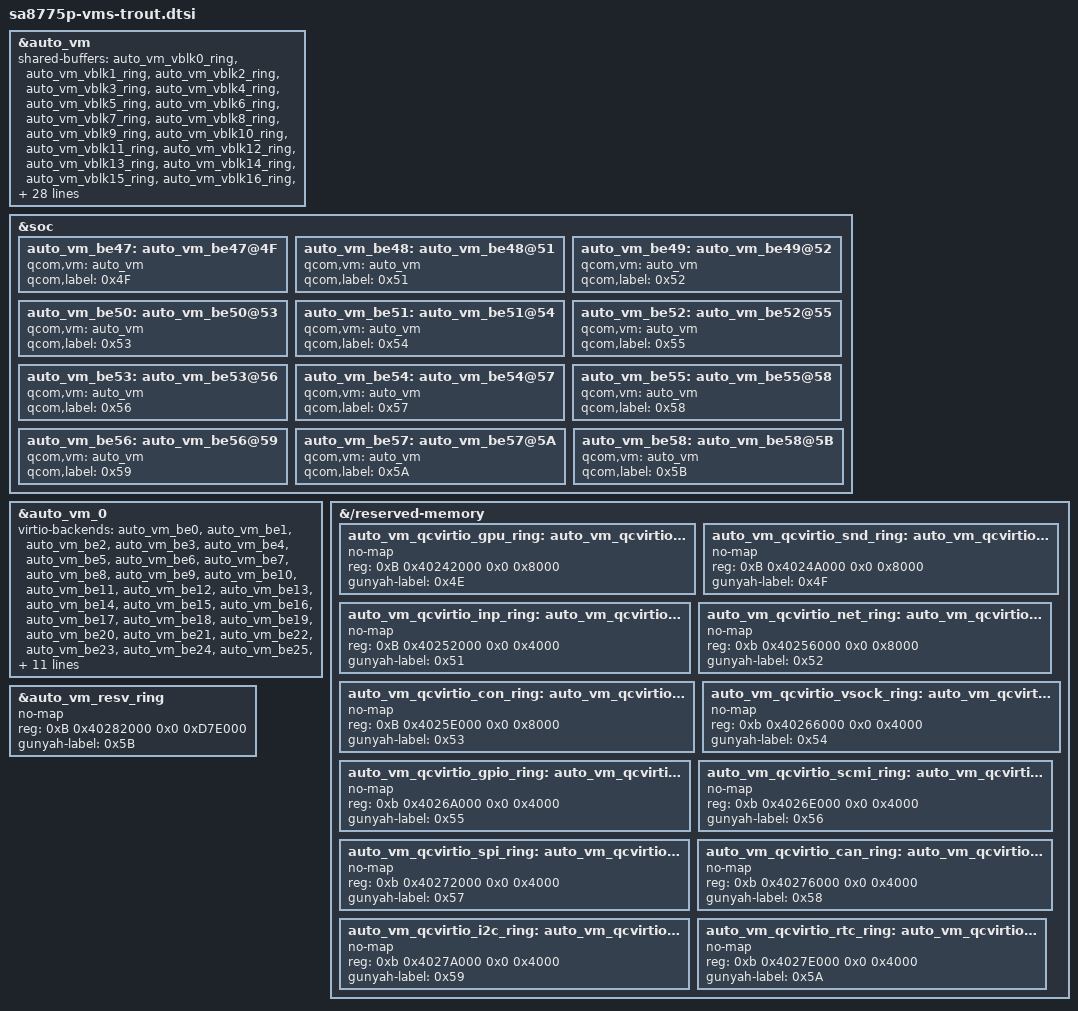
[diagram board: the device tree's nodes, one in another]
// SPDX-License-Identifier: BSD-3-Clause
/*
 * Copyright (c) Qualcomm Technologies, Inc. and/or its subsidiaries.
 */

&auto_vm {
	shared-buffers = <&auto_vm_vblk0_ring
				&auto_vm_vblk1_ring
				&auto_vm_vblk2_ring
				&auto_vm_vblk3_ring
				&auto_vm_vblk4_ring
				&auto_vm_vblk5_ring
				&auto_vm_vblk6_ring
				&auto_vm_vblk7_ring
				&auto_vm_vblk8_ring
				&auto_vm_vblk9_ring
				&auto_vm_vblk10_ring
				&auto_vm_vblk11_ring
				&auto_vm_vblk12_ring
				&auto_vm_vblk13_ring
				&auto_vm_vblk14_ring
				&auto_vm_vblk15_ring
				&auto_vm_vblk16_ring
				&auto_vm_vblk17_ring
				&auto_vm_vblk18_ring
				&auto_vm_vblk19_ring
				&auto_vm_vblk20_ring
				&auto_vm_vblk21_ring
				&auto_vm_vblk22_ring
				&auto_vm_vblk23_ring
				&auto_vm_vblk24_ring
				&auto_vm_vnet0_ring
				&auto_vm_vnet1_ring
				&auto_vm_vhab0_ring
				&auto_vm_vhab1_ring
				&auto_vm_vhab2_ring
				&auto_vm_vhab3_ring
				&auto_vm_vhab4_ring
				&auto_vm_vhab5_ring
				&auto_vm_vhab6_ring
				&auto_vm_vhab7_ring
				&auto_vm_vhab8_ring
				&auto_vm_input0_ring
				&auto_vm_input1_ring
				&auto_vm_vconsole_ring
				&auto_vm_vscmi_ring
				&auto_vm_vsock_ring
				&auto_vm_glink_ring
				&auto_vm_frpc_ring
				&auto_vm_i2c0_ring
				&auto_vm_ssr_ring
				&auto_vm_eavb_ring
				&auto_vm_qcvirtio_gpu_ring
				&auto_vm_qcvirtio_snd_ring
				&auto_vm_qcvirtio_inp_ring
				&auto_vm_qcvirtio_net_ring
				&auto_vm_qcvirtio_con_ring
				&auto_vm_qcvirtio_vsock_ring
				&auto_vm_qcvirtio_gpio_ring
				&auto_vm_qcvirtio_scmi_ring
				&auto_vm_qcvirtio_spi_ring
				&auto_vm_qcvirtio_can_ring
				&auto_vm_qcvirtio_i2c_ring
				&auto_vm_qcvirtio_rtc_ring
				&auto_vm_resv_ring
				&auto_vm_swiotlb
				>;
};

&soc {
	auto_vm_be47: auto_vm_be47@4F {
		qcom,vm = <&auto_vm>;
		qcom,label = <0x4F>;
	};

	auto_vm_be48: auto_vm_be48@51 {
		qcom,vm = <&auto_vm>;
		qcom,label = <0x51>;
	};

	auto_vm_be49: auto_vm_be49@52 {
		qcom,vm = <&auto_vm>;
		qcom,label = <0x52>;
	};

	auto_vm_be50: auto_vm_be50@53 {
		qcom,vm = <&auto_vm>;
		qcom,label = <0x53>;
	};

	auto_vm_be51: auto_vm_be51@54 {
		qcom,vm = <&auto_vm>;
		qcom,label = <0x54>;
	};

	auto_vm_be52: auto_vm_be52@55 {
		qcom,vm = <&auto_vm>;
		qcom,label = <0x55>;
	};

	auto_vm_be53: auto_vm_be53@56 {
		qcom,vm = <&auto_vm>;
		qcom,label = <0x56>;
	};

	auto_vm_be54: auto_vm_be54@57 {
		qcom,vm = <&auto_vm>;
		qcom,label = <0x57>;
	};

	auto_vm_be55: auto_vm_be55@58 {
		qcom,vm = <&auto_vm>;
		qcom,label = <0x58>;
	};

	auto_vm_be56: auto_vm_be56@59 {
		qcom,vm = <&auto_vm>;
		qcom,label = <0x59>;
	};

	auto_vm_be57: auto_vm_be57@5A {
		qcom,vm = <&auto_vm>;
		qcom,label = <0x5A>;
	};

	auto_vm_be58: auto_vm_be58@5B {
		qcom,vm = <&auto_vm>;
		qcom,label = <0x5B>;
	};
};

&auto_vm_0 {
	virtio-backends = <&auto_vm_be0
				&auto_vm_be1
				&auto_vm_be2
				&auto_vm_be3
				&auto_vm_be4
				&auto_vm_be5
				&auto_vm_be6
				&auto_vm_be7
				&auto_vm_be8
				&auto_vm_be9
				&auto_vm_be10
				&auto_vm_be11
				&auto_vm_be12
				&auto_vm_be13
				&auto_vm_be14
				&auto_vm_be15
				&auto_vm_be16
				&auto_vm_be17
				&auto_vm_be18
				&auto_vm_be19
				&auto_vm_be20
				&auto_vm_be21
				&auto_vm_be22
				&auto_vm_be23
				&auto_vm_be24
				&auto_vm_be25
				&auto_vm_be26
				&auto_vm_be27
				&auto_vm_be28
				&auto_vm_be29
				&auto_vm_be30
				&auto_vm_be31
				&auto_vm_be32
				&auto_vm_be33
				&auto_vm_be34
				&auto_vm_be35
				&auto_vm_be36
				&auto_vm_be37
				&auto_vm_be38
				&auto_vm_be39
				&auto_vm_be40
				&auto_vm_be41
				&auto_vm_be42
				&auto_vm_be43
				&auto_vm_be44
				&auto_vm_be45
				&auto_vm_be46
				&auto_vm_be47
				&auto_vm_be48
				&auto_vm_be49
				&auto_vm_be50
				&auto_vm_be51
				&auto_vm_be52
				&auto_vm_be53
				&auto_vm_be54
				&auto_vm_be55
				&auto_vm_be56
				&auto_vm_be57
				&auto_vm_be58
				>;
};

&{/reserved-memory} {
	auto_vm_qcvirtio_gpu_ring: auto_vm_qcvirtio_gpu_ring@B40242000 {
		no-map;
		reg = <0xB 0x40242000 0x0 0x8000>;
		gunyah-label = <0x4E>;
	};

	auto_vm_qcvirtio_snd_ring: auto_vm_qcvirtio_snd_ring@B4024A000 {
		no-map;
		reg = <0xB 0x4024A000 0x0 0x8000>;
		gunyah-label = <0x4F>;
	};

	auto_vm_qcvirtio_inp_ring: auto_vm_qcvirtio_inp_ring@B40252000 {
		no-map;
		reg = <0xB 0x40252000 0x0 0x4000>;
		gunyah-label = <0x51>;
	};

	auto_vm_qcvirtio_net_ring: auto_vm_qcvirtio_net_ring@B40256000 {
		no-map;
		reg = <0xb 0x40256000 0x0 0x8000>;
		gunyah-label = <0x52>;
	};

	auto_vm_qcvirtio_con_ring: auto_vm_qcvirtio_con_ring@B4025E000 {
		no-map;
		reg = <0xB 0x4025E000 0x0 0x8000>;
		gunyah-label = <0x53>;
	};

	auto_vm_qcvirtio_vsock_ring: auto_vm_qcvirtio_vsock_ring@B40266000 {
		no-map;
		reg = <0xb 0x40266000 0x0 0x4000>;
		gunyah-label = <0x54>;
	};

	auto_vm_qcvirtio_gpio_ring: auto_vm_qcvirtio_gpio_ring@B4026A000 {
		no-map;
		reg = <0xb 0x4026A000 0x0 0x4000>;
		gunyah-label = <0x55>;
	};

	auto_vm_qcvirtio_scmi_ring: auto_vm_qcvirtio_scmi_ring@B4026E000 {
		no-map;
		reg = <0xb 0x4026E000 0x0 0x4000>;
		gunyah-label = <0x56>;
	};

	auto_vm_qcvirtio_spi_ring: auto_vm_qcvirtio_spi_ring@B40272000 {
		no-map;
		reg = <0xb 0x40272000 0x0 0x4000>;
		gunyah-label = <0x57>;
	};

	auto_vm_qcvirtio_can_ring: auto_vm_qcvirtio_can_ring@B40276000 {
		no-map;
		reg = <0xb 0x40276000 0x0 0x4000>;
		gunyah-label = <0x58>;
	};

	auto_vm_qcvirtio_i2c_ring: auto_vm_qcvirtio_i2c_ring@B4027A000 {
		no-map;
		reg = <0xb 0x4027A000 0x0 0x4000>;
		gunyah-label = <0x59>;
	};

	auto_vm_qcvirtio_rtc_ring: auto_vm_qcvirtio_rtc_ring@B4027E000 {
		no-map;
		reg = <0xb 0x4027E000 0x0 0x4000>;
		gunyah-label = <0x5A>;
	};
};

&auto_vm_resv_ring {
	no-map;
	reg = <0xB 0x40282000 0x0 0xD7E000>;
	gunyah-label = <0x5B>;
};
